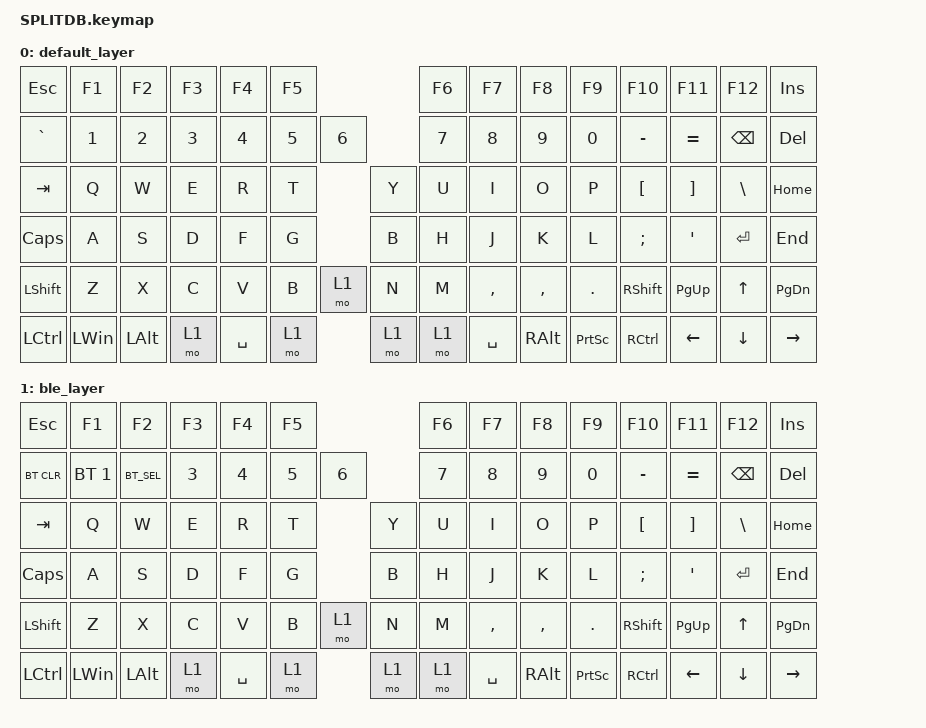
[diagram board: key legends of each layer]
#include <behaviors.dtsi>
#include <dt-bindings/zmk/keys.h>
#include <dt-bindings/zmk/bt.h>
#define DEFAULT 0
#define BLE     1

/ {
    keymap {
        compatible = "zmk,keymap";

        default_layer {

            bindings = <
        &kp ESC       &kp F1        &kp F2        &kp F3        &kp F4        &kp F5                                    &kp F6        &kp F7        &kp F8        &kp F9        &kp F10       &kp F11       &kp F12       &kp INSERT    
        &kp GRAVE     &kp N1        &kp N2        &kp N3        &kp N4        &kp N5        &kp N6                      &kp N7        &kp N8        &kp N9        &kp N0        &kp MINUS     &kp EQUAL     &kp BSPC      &kp DEL       
        &kp TAB       &kp Q         &kp W         &kp E         &kp R         &kp T                       &kp Y         &kp U         &kp I         &kp O         &kp P         &kp LBKT      &kp RBKT      &kp BSLH      &kp HOME      
        &kp CAPS      &kp A         &kp S         &kp D         &kp F         &kp G                       &kp B         &kp H         &kp J         &kp K         &kp L         &kp SEMI      &kp SQT       &kp ENTER     &kp END       
        &kp LSHFT     &kp Z         &kp X         &kp C         &kp V         &kp B         &mo 1         &kp N         &kp M         &kp COMMA     &kp COMMA     &kp DOT       &kp RSHFT     &kp PAGE_UP   &kp UP        &kp PAGE_DOWN 
        &kp LCTRL     &kp LEFT_WIN  &kp LALT      &mo 1         &kp SPACE     &mo 1                       &mo 1         &mo 1         &kp SPACE     &kp RALT      &kp PSCRN     &kp RCTRL     &kp LEFT      &kp DOWN      &kp RIGHT     
            >;
        };

        ble_layer {

            bindings = <
        &kp ESC       &kp F1        &kp F2        &kp F3        &kp F4        &kp F5                                    &kp F6        &kp F7        &kp F8        &kp F9        &kp F10       &kp F11       &kp F12       &kp INSERT    
        &bt BT_CLR    &bt BT_SEL 1  &kp BT_SEL 2  &kp N3        &kp N4        &kp N5        &kp N6                      &kp N7        &kp N8        &kp N9        &kp N0        &kp MINUS     &kp EQUAL     &kp BSPC      &kp DEL       
        &kp TAB       &kp Q         &kp W         &kp E         &kp R         &kp T                       &kp Y         &kp U         &kp I         &kp O         &kp P         &kp LBKT      &kp RBKT      &kp BSLH      &kp HOME      
        &kp CAPS      &kp A         &kp S         &kp D         &kp F         &kp G                       &kp B         &kp H         &kp J         &kp K         &kp L         &kp SEMI      &kp SQT       &kp ENTER     &kp END       
        &kp LSHFT     &kp Z         &kp X         &kp C         &kp V         &kp B         &mo 1         &kp N         &kp M         &kp COMMA     &kp COMMA     &kp DOT       &kp RSHFT     &kp PAGE_UP   &kp UP        &kp PAGE_DOWN 
        &kp LCTRL     &kp LEFT_WIN  &kp LALT      &mo 1         &kp SPACE     &mo 1                       &mo 1         &mo 1         &kp SPACE     &kp RALT      &kp PSCRN     &kp RCTRL     &kp LEFT      &kp DOWN      &kp RIGHT     
            >;
        };
    };
};

